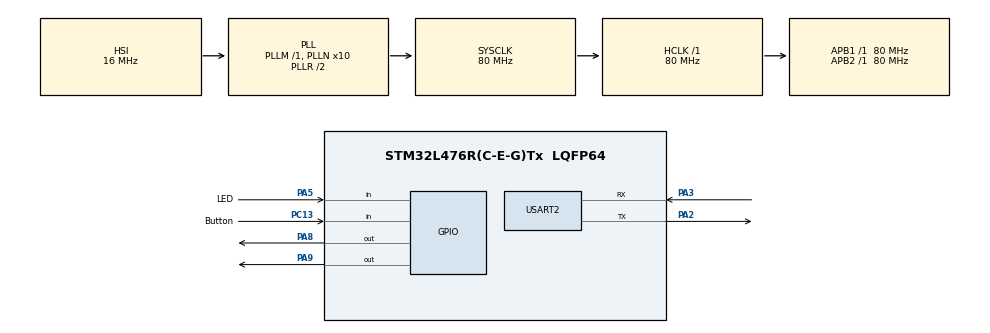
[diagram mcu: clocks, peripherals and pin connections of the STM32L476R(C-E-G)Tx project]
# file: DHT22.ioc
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Mcu.Family=STM32L4
Mcu.Name=STM32L476R(C-E-G)Tx
Mcu.Package=LQFP64
NVIC.PriorityGroup=NVIC_PRIORITYGROUP_4
PA2.Mode=Asynchronous
PA2.Signal=USART2_TX
PA3.Mode=Asynchronous
PA3.Signal=USART2_RX
PA5.GPIO_Label=LED
PA5.Signal=GPIO_Input
PA8.Signal=GPIO_Output
PA9.Signal=GPIO_Output
PC13.GPIO_Label=Button
PC13.Signal=GPIO_Input
ProjectManager.HeapSize=0x200
ProjectManager.StackSize=0x400
ProjectManager.TargetToolchain=MDK-ARM V5.27
RCC.ADCFreq_Value=64000000
RCC.AHBFreq_Value=80000000
RCC.APB1Freq_Value=80000000
RCC.APB1TimFreq_Value=80000000
RCC.APB2Freq_Value=80000000
RCC.APB2TimFreq_Value=80000000
RCC.CortexFreq_Value=80000000
RCC.HCLKFreq_Value=80000000
RCC.HSE_VALUE=8000000
RCC.HSI_VALUE=16000000
RCC.LSE_VALUE=32768
RCC.MSI_VALUE=4000000
RCC.PLLN=10
RCC.PLLSourceVirtual=RCC_PLLSOURCE_HSI
RCC.PREFETCH_ENABLE=1
RCC.SYSCLKFreq_VALUE=80000000
RCC.SYSCLKSource=RCC_SYSCLKSOURCE_PLLCLK
RCC.USBFreq_Value=64000000
RCC.VCOOutputFreq_Value=160000000
USART2.VirtualMode-Asynchronous=VM_ASYNC
board=NUCLEO-L476RG

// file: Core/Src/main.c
/* USER CODE BEGIN Header */
/**
  ******************************************************************************
  * @file           : main.c
  * @brief          : Main program body
  ******************************************************************************
  * @attention
  *
  * <h2><center>&copy; Copyright (c) 2021 STMicroelectronics.
  * All rights reserved.</center></h2>
  *
  * This software component is licensed by ST under BSD 3-Clause license,
  * the "License"; You may not use this file except in compliance with the
  * License. You may obtain a copy of the License at:
  *                        opensource.org/licenses/BSD-3-Clause
  *
  ******************************************************************************
  */
/* USER CODE END Header */
#include "main.h"
#include "usart.h"
#include "gpio.h"

/* USER CODE BEGIN Includes */
#include "MY_DHT22.h"
//#include "lib_lcd.h"

/* USER CODE END Includes */

/* USER CODE BEGIN PTD */
//static rgb_lcd lcdData;
/* USER CODE END PTD */

/* USER CODE BEGIN PM */
 //lcd_init(&hi2c1, &lcdData); // initialise le lcd
 // lcd_position(&hi2c1,0,0);
  //lcd_print(&hi2c1,"Pause CAFE 10h");
 // reglagecouleur(0,0,255);
// HAL_Delay(1000);

/* USER CODE END PM */

void SystemClock_Config(void);

/* USER CODE BEGIN 0 */
float TempC, Humidity;
char uartData[50];
/* USER CODE END 0 */

int main(void)
{

  /* MCU Configuration--------------------------------------------------------*/

  /* Reset of all peripherals, Initializes the Flash interface and the Systick. */
  HAL_Init();

  /* Configure the system clock */
  SystemClock_Config();

  /* Initialize all configured peripherals */
  MX_GPIO_Init();
  MX_USART2_UART_Init();
  /* USER CODE BEGIN 2 */
DHT22_Init(GPIOA, GPIO_PIN_9);
  /* USER CODE END 2 */

  /* Infinite loop */
  while (1)
  {

    /* USER CODE BEGIN 3 */
		if(DHT22_GetTemp_Humidity(&TempC, &Humidity) == 1)
		{
			sprintf(uartData, "\r\nTemp (C) =\t %.1f\r\nHumidity (%%) =\t %.1f%%\r\n", TempC, Humidity);
			HAL_UART_Transmit(&huart2, (uint8_t *)uartData, strlen(uartData), 10);
		}
		else
		{
			sprintf(uartData, "\r\nCRC Error!\r\n");
			HAL_UART_Transmit(&huart2, (uint8_t *)uartData, strlen(uartData), 10);
		}

		HAL_Delay(1000);
	/*	lcd_position(&hi2c1,0,0);
		lcd_print(&hi2c1,"la temp(C):%.1f",TempC);
		lcd_position(&hi2c1,0,1);
		lcd_print(&hi2c1,"l'humiditИ:%.1f",Humidity);*/

  }
  /* USER CODE END 3 */
}

void SystemClock_Config(void)
{
  RCC_OscInitTypeDef RCC_OscInitStruct = {0};
  RCC_ClkInitTypeDef RCC_ClkInitStruct = {0};
  RCC_PeriphCLKInitTypeDef PeriphClkInit = {0};

  /** Initializes the RCC Oscillators according to the specified parameters
  * in the RCC_OscInitTypeDef structure.
  */
  RCC_OscInitStruct.OscillatorType = RCC_OSCILLATORTYPE_HSI;
  RCC_OscInitStruct.HSIState = RCC_HSI_ON;
  RCC_OscInitStruct.HSICalibrationValue = RCC_HSICALIBRATION_DEFAULT;
  RCC_OscInitStruct.PLL.PLLState = RCC_PLL_ON;
  RCC_OscInitStruct.PLL.PLLSource = RCC_PLLSOURCE_HSI;
  RCC_OscInitStruct.PLL.PLLM = 1;
  RCC_OscInitStruct.PLL.PLLN = 10;
  RCC_OscInitStruct.PLL.PLLP = RCC_PLLP_DIV7;
  RCC_OscInitStruct.PLL.PLLQ = RCC_PLLQ_DIV2;
  RCC_OscInitStruct.PLL.PLLR = RCC_PLLR_DIV2;
  if (HAL_RCC_OscConfig(&RCC_OscInitStruct) != HAL_OK)
  {
    Error_Handler();
  }
  /** Initializes the CPU, AHB and APB buses clocks
  */
  RCC_ClkInitStruct.ClockType = RCC_CLOCKTYPE_HCLK|RCC_CLOCKTYPE_SYSCLK
                              |RCC_CLOCKTYPE_PCLK1|RCC_CLOCKTYPE_PCLK2;
  RCC_ClkInitStruct.SYSCLKSource = RCC_SYSCLKSOURCE_PLLCLK;
  RCC_ClkInitStruct.AHBCLKDivider = RCC_SYSCLK_DIV1;
  RCC_ClkInitStruct.APB1CLKDivider = RCC_HCLK_DIV1;
  RCC_ClkInitStruct.APB2CLKDivider = RCC_HCLK_DIV1;

  if (HAL_RCC_ClockConfig(&RCC_ClkInitStruct, FLASH_LATENCY_4) != HAL_OK)
  {
    Error_Handler();
  }
  PeriphClkInit.PeriphClockSelection = RCC_PERIPHCLK_USART2;
  PeriphClkInit.Usart2ClockSelection = RCC_USART2CLKSOURCE_PCLK1;
  if (HAL_RCCEx_PeriphCLKConfig(&PeriphClkInit) != HAL_OK)
  {
    Error_Handler();
  }
  /** Configure the main internal regulator output voltage
  */
  if (HAL_PWREx_ControlVoltageScaling(PWR_REGULATOR_VOLTAGE_SCALE1) != HAL_OK)
  {
    Error_Handler();
  }
}

void Error_Handler(void)
{
  __disable_irq();
  while (1)
  {
  }
}

/************************ (C) COPYRIGHT STMicroelectronics *****END OF FILE****/
